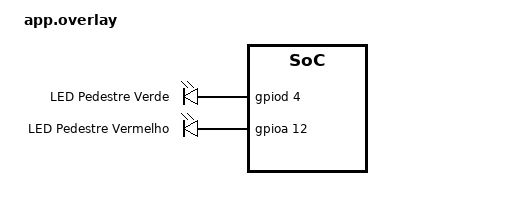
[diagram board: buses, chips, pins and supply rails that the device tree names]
/ {
    aliases {
        led-ped-verde = &ext_led_d;
        led-ped-verm = &ext_led_e;
    };

    leds_externos {
        compatible = "gpio-leds";
        ext_led_d: led_d {
            gpios = <&gpiod 4 GPIO_ACTIVE_HIGH>; /* PTD4 (Pino D2 Arduino) */
            label = "LED Pedestre Verde";
        };
        ext_led_e: led_e {
            gpios = <&gpioa 12 GPIO_ACTIVE_HIGH>; /* PTA12 (Pino D3 Arduino) */
            label = "LED Pedestre Vermelho";
        };
    };
};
